AUTOSAR XML (schema 00048)
package /MICROSAR/BswM_swc
  mode declaration group ESH_Mode: category=EXPLICIT_ORDER, initial-mode=STARTUP, on-transition-value=5
    5 x mode:
      STARTUP: value=0
      RUN: value=1
      POSTRUN: value=2
      WAKEUP: value=3
      SHUTDOWN: value=4
  mode declaration group ESH_RunRequest: category=EXPLICIT_ORDER, initial-mode=RELEASED, on-transition-value=2
    mode RELEASED: value=0
    mode REQUESTED: value=1
  data type mapping set BswMMappingSet  # Contains Mapping for ModeDeclarations Groups which are provided by BswM.
    mode-request-type-maps:
      implementation-data-type=BswM_ESH_Mode, mode-group=ESH_Mode
      implementation-data-type=BswM_ESH_RunRequest, mode-group=ESH_RunRequest
package /MICROSAR/BswM_swc/ComponentTypes
  service sw component type BswM_OsApplication_SystemApplication_Core1: category=SERVICE_COMPONENT
    behavior BswM_OsApplication_SystemApplication_Core1InternalBehavior: data-type-mapping=BswMMappingSet, handle-termination-and-restart=NO-SUPPORT
      timing event Timer_BswM_MainFunction_OsApplication_SystemApplication_Core1: start-on-event=BswM_MainFunction_OsApplication_SystemApplication_Core1, period=0.01
      runnable BswM_MainFunction_OsApplication_SystemApplication_Core1
  swc implementation BswM_OsApplication_SystemApplication_Core1Implementation: programming-language=C, behavior=BswM_OsApplication_SystemApplication_Core1InternalBehavior
    resource consumption BswM_OsApplication_SystemApplication_Core1ResourceConsumption
      5 x memory section:
        BswM_OsApplication_SystemApplication_Core1_START_SEC_CODE: sw-addrmethod=CODE, symbol=CODE
        BswM_OsApplication_SystemApplication_Core1_START_SEC_CONST_UNSPECIFIED: alignment=UNSPECIFIED, sw-addrmethod=CONST, symbol=CONST_UNSPECIFIED
        BswM_OsApplication_SystemApplication_Core1_START_SEC_VAR_NOINIT_UNSPECIFIED: alignment=UNSPECIFIED, sw-addrmethod=VAR_NO_INIT, symbol=VAR_NOINIT_UNSPECIFIED
        BswM_OsApplication_SystemApplication_Core1_START_SEC_VAR_INIT_UNSPECIFIED: alignment=UNSPECIFIED, sw-addrmethod=VAR_INIT, symbol=VAR_INIT_UNSPECIFIED
        BswM_OsApplication_SystemApplication_Core1_START_SEC_VAR_ZERO_INIT_UNSPECIFIED: alignment=UNSPECIFIED, sw-addrmethod=VAR_CLEARED, symbol=VAR_ZERO_INIT_UNSPECIFIED
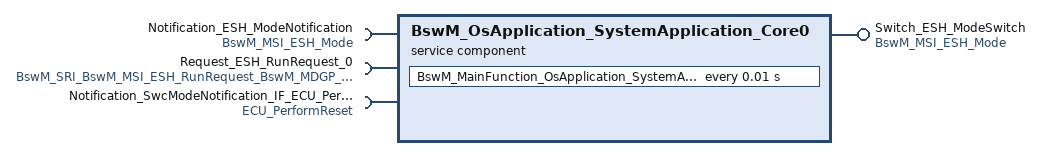
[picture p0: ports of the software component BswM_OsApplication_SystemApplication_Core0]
  service sw component type BswM_OsApplication_SystemApplication_Core0: category=SERVICE_COMPONENT
    provide port Switch_ESH_ModeSwitch: provided-interface=BswM_MSI_ESH_Mode
    require port Notification_ESH_ModeNotification: required-interface=BswM_MSI_ESH_Mode
    require port Request_ESH_RunRequest_0: nonqueued-receiver-com-spec{data-element=BswM_SRI_BswM_MSI_ESH_RunRequest_BswM_MDGP_ESH_RunRequest/requestedMode, handle-out-of-range-status=SILENT, init-value=RELEASED}, required-interface=BswM_SRI_BswM_MSI_ESH_RunRequest_BswM_MDGP_ESH_RunRequest
    require port Notification_SwcModeNotification_IF_ECU_Perform_Reset_Indication: required-interface=ECU_PerformReset
    behavior BswM_OsApplication_SystemApplication_Core0InternalBehavior: data-type-mapping=BswMMappingSet, handle-termination-and-restart=NO-SUPPORT, included-data-type-set=data-type=[BswM_ESH_Mode, BswM_ESH_RunRequest]
      timing event Timer_BswM_MainFunction_OsApplication_SystemApplication_Core0: start-on-event=BswM_MainFunction_OsApplication_SystemApplication_Core0, period=0.01
      port-api-options:
        enable-take-address=true, indirect-api=false, port=Switch_ESH_ModeSwitch
        enable-take-address=true, indirect-api=false, port=Notification_ESH_ModeNotification
        enable-take-address=true, indirect-api=false, port=Request_ESH_RunRequest_0
        enable-take-address=true, indirect-api=false, port=Notification_SwcModeNotification_IF_ECU_Perform_Reset_Indication
      runnable BswM_MainFunction_OsApplication_SystemApplication_Core0
        data-receive-point-by-arguments:
          access DataReceivePointBswM_MainFunction_OsApplication_SystemApplication_Core0_Request_ESH_RunRequest_0_requestedMode: accessed-variable=Request_ESH_RunRequest_0.requestedMode
        mode-access-points:
          Notification_ESH_ModeNotification.BswM_MDGP_ESH_Mode
          Notification_SwcModeNotification_IF_ECU_Perform_Reset_Indication.IF_ECU_Perform_Reset_Indication
        mode switch point ModeSwitchPointBswM_MainFunction_OsApplication_SystemApplication_Core0_Switch_ESH_ModeSwitch_BswM_MDGP_ESH_Mode: mode-group=Switch_ESH_ModeSwitch.BswM_MDGP_ESH_Mode
  swc implementation BswM_OsApplication_SystemApplication_Core0Implementation: programming-language=C, behavior=BswM_OsApplication_SystemApplication_Core0InternalBehavior
    resource consumption BswM_OsApplication_SystemApplication_Core0ResourceConsumption
      5 x memory section:
        BswM_OsApplication_SystemApplication_Core0_START_SEC_CODE: sw-addrmethod=CODE, symbol=CODE
        BswM_OsApplication_SystemApplication_Core0_START_SEC_CONST_UNSPECIFIED: alignment=UNSPECIFIED, sw-addrmethod=CONST, symbol=CONST_UNSPECIFIED
        BswM_OsApplication_SystemApplication_Core0_START_SEC_VAR_NOINIT_UNSPECIFIED: alignment=UNSPECIFIED, sw-addrmethod=VAR_NO_INIT, symbol=VAR_NOINIT_UNSPECIFIED
        BswM_OsApplication_SystemApplication_Core0_START_SEC_VAR_INIT_UNSPECIFIED: alignment=UNSPECIFIED, sw-addrmethod=VAR_INIT, symbol=VAR_INIT_UNSPECIFIED
        BswM_OsApplication_SystemApplication_Core0_START_SEC_VAR_ZERO_INIT_UNSPECIFIED: alignment=UNSPECIFIED, sw-addrmethod=VAR_CLEARED, symbol=VAR_ZERO_INIT_UNSPECIFIED
package /MICROSAR/BswM_swc/DataTypes
  impl type BswM_ESH_Mode: compu {0=STARTUP, 1=RUN, 2=POSTRUN, 3=WAKEUP, 4=SHUTDOWN}, range raw 0..255, implementation-data-type=uint8  # Unique value for each user
  impl type BswM_ESH_RunRequest: compu {0=RELEASED, 1=REQUESTED}, range raw 0..255, implementation-data-type=uint8  # Unique value for each user
package /MICROSAR/BswM_swc/Interfaces
  mode switch interface BswM_MSI_ESH_Mode: is-service=true, service-kind=BASIC-SOFTWARE-MODE-MANAGER
    mode group BswM_MDGP_ESH_Mode: type=ESH_Mode
  sender receiver interface BswM_SRI_BswM_MSI_ESH_Mode_BswM_MDGP_ESH_Mode: is-service=true, service-kind=BASIC-SOFTWARE-MODE-MANAGER
    data requestedMode: type=BswM_ESH_Mode
  mode switch interface BswM_MSI_ESH_RunRequest: is-service=true, service-kind=BASIC-SOFTWARE-MODE-MANAGER
    mode group BswM_MDGP_ESH_RunRequest: type=ESH_RunRequest
  sender receiver interface BswM_SRI_BswM_MSI_ESH_RunRequest_BswM_MDGP_ESH_RunRequest: is-service=true, service-kind=BASIC-SOFTWARE-MODE-MANAGER
    data requestedMode: type=BswM_ESH_RunRequest
